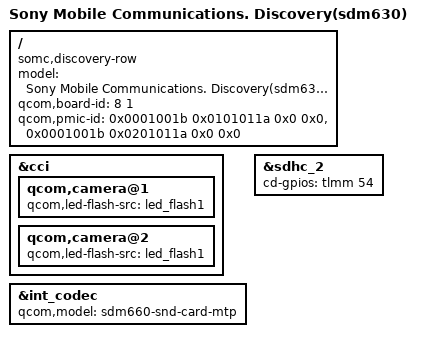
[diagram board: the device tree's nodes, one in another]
/* Copyright (c) 2017, The Linux Foundation. All rights reserved.
 *
 * This program is free software; you can redistribute it and/or modify
 * it under the terms of the GNU General Public License version 2 and
 * only version 2 as published by the Free Software Foundation.
 *
 * This program is distributed in the hope that it will be useful,
 * but WITHOUT ANY WARRANTY; without even the implied warranty of
 * MERCHANTABILITY or FITNESS FOR A PARTICULAR PURPOSE.  See the
 * GNU General Public License for more details.
 */


/dts-v1/;

#include "../qcom/sdm630.dtsi"
#include "../qcom/sdm630-mtp.dtsi"
#include "../qcom/sdm660-internal-codec.dtsi"
#include "sdm630-ganges-pioneer.dtsi"

/ {
	model = "Sony Mobile Communications. Discovery(sdm630)";
	compatible = "somc,discovery-row", "qcom,sdm630-mtp", "qcom,sdm630", "qcom,mtp";
	qcom,board-id = <8 1>;
	qcom,pmic-id = <0x0001001b 0x0101011a 0x0 0x0>,
			<0x0001001b 0x0201011a 0x0 0x0>;
};

&cci {
	qcom,camera@1 {
		qcom,led-flash-src = <&led_flash1>;
	};

	qcom,camera@2 {
		qcom,led-flash-src = <&led_flash1>;
	};
};

&int_codec {
	qcom,model = "sdm660-snd-card-mtp";
};

&sdhc_2 {
	cd-gpios = <&tlmm 54 0x0>;
};
